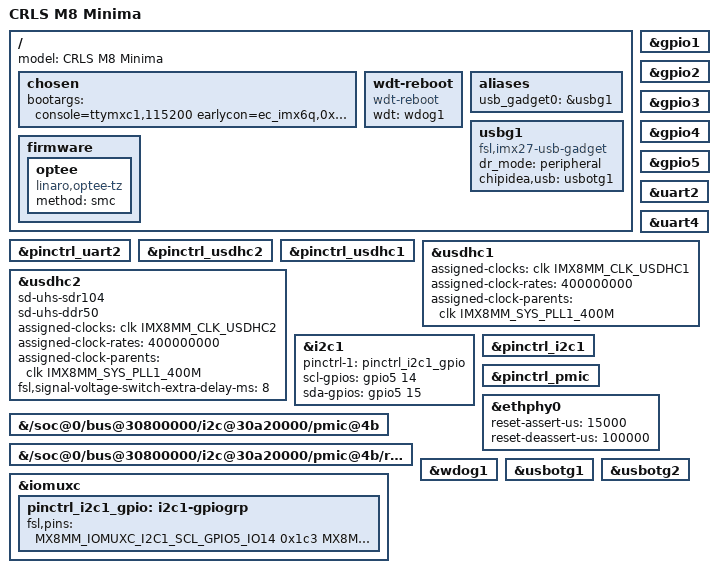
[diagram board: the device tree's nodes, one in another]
// SPDX-License-Identifier: GPL-2.0+
/*
 * Copyright 2020 NXP
 */

#include "imx8mm-u-boot.dtsi"

/ {
	model = "CRLS M8 Minima";

	chosen {
		bootargs = "console=ttymxc1,115200 earlycon=ec_imx6q,0x30890000,115200";
	};

	wdt-reboot {
		compatible = "wdt-reboot";
		wdt = <&wdog1>;
		bootph-pre-ram;
	};

	aliases {
		usb_gadget0 = &usbg1;
	};

	usbg1: usbg1 {
		compatible = "fsl,imx27-usb-gadget";
		dr_mode = "peripheral";
		chipidea,usb = <&usbotg1>;
		status = "okay";
	};

	firmware {
		optee {
			compatible = "linaro,optee-tz";
			method = "smc";
		};
	};
};

&pinctrl_uart2 {
	bootph-pre-ram;
};

&pinctrl_usdhc2 {
	bootph-pre-ram;
};

&pinctrl_usdhc1 {
	bootph-pre-ram;
};

&gpio1 {
	bootph-pre-ram;
};

&gpio2 {
	bootph-pre-ram;
};

&gpio3 {
	bootph-pre-ram;
};

&gpio4 {
	bootph-pre-ram;
};

&gpio5 {
	bootph-pre-ram;
};

&uart2 {
	bootph-pre-ram;
};

&uart4 {
	bootph-pre-ram;
};

/*
 * eMMC VCCQ is hard-wired to 1.8 V. U-Boot's esdhc driver tries to
 * regulator_set_value() any vqmmc-supply and fails on a fixed regulator,
 * so drop it here (the kernel DT keeps it).
 */
&usdhc1 {
	/delete-property/ vqmmc-supply;
	bootph-pre-ram;
	assigned-clocks = <&clk IMX8MM_CLK_USDHC1>;
	assigned-clock-rates = <400000000>;
	assigned-clock-parents = <&clk IMX8MM_SYS_PLL1_400M>;
};

&usdhc2 {
	bootph-pre-ram;
	sd-uhs-sdr104;
	sd-uhs-ddr50;
	assigned-clocks = <&clk IMX8MM_CLK_USDHC2>;
	assigned-clock-rates = <400000000>;
	assigned-clock-parents = <&clk IMX8MM_SYS_PLL1_400M>;
	fsl,signal-voltage-switch-extra-delay-ms = <8>;
};

&i2c1 {
	pinctrl-names = "default", "gpio";
	pinctrl-1 = <&pinctrl_i2c1_gpio>;
	scl-gpios = <&gpio5 14 GPIO_ACTIVE_HIGH>;
	sda-gpios = <&gpio5 15 GPIO_ACTIVE_HIGH>;
	bootph-pre-ram;
};

&{/soc@0/bus@30800000/i2c@30a20000/pmic@4b} {
	bootph-pre-ram;
};

&{/soc@0/bus@30800000/i2c@30a20000/pmic@4b/regulators} {
	bootph-pre-ram;
};

&pinctrl_i2c1 {
	bootph-pre-ram;
};

&pinctrl_pmic {
	bootph-pre-ram;
};

/* RTL8211F: >=10 ms reset pulse, >=72 ms before first MDIO access */
&ethphy0 {
	reset-assert-us = <15000>;
	reset-deassert-us = <100000>;
};

&wdog1 {
	bootph-pre-ram;
};

&usbotg1 {
	status = "okay";
	/delete-property/ extcon;
};

&usbotg2 {
	bootph-pre-ram;
};

&iomuxc {
	pinctrl_i2c1_gpio: i2c1-gpiogrp {
		fsl,pins = <
			MX8MM_IOMUXC_I2C1_SCL_GPIO5_IO14	0x1c3
			MX8MM_IOMUXC_I2C1_SDA_GPIO5_IO15	0x1c3
		>;
	};
};
